VERSION ""

NS_ :

BS_:

BU_: GearboxECU EngineECU

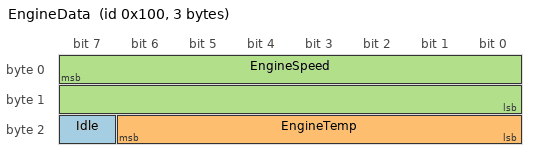
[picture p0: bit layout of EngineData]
BO_ 256 EngineData: 3 EngineECU
 SG_ Idle : 23|1@0+ (1,0) [0|1] "" Vector__XXX
 SG_ EngineTemp : 22|7@0+ (2,-50) [-50|204] "¡ÆC" Vector__XXX
 SG_ EngineSpeed : 7|16@0+ (1,0) [0|65535] "rpm"  GearboxECU

EV_ EnvKlemme30: 0 [0|1] "" 1 1 DUMMY_NODE_VECTOR0 Vector__XXX;

EV_ EnvKlemme15: 0 [0|1] "" 0 2 DUMMY_NODE_VECTOR0 Vector__XXX;

BA_DEF_ BU_  "NodeLayerModules" STRING ;
BA_DEF_ BO_  "GenMsgILSupport" ENUM  "No","Yes";
BA_DEF_  "NmBaseAddress" HEX 1024 1087;
BA_DEF_ BO_  "GenMsgCycleTime" INT 0 50000;
BA_DEF_ BO_  "GenMsgSendType" ENUM  "Cyclic","NotUsed","NotUsed","NotUsed","NotUsed","NotUsed","NotUsed","IfActive","NoMsgSendType","NotUsed","vector_leerstring";
BA_DEF_ SG_  "GenSigSendType" ENUM  "Cyclic","OnWrite","OnWriteWithRepetition","OnChange","OnChangeWithRepetition","IfActive","IfActiveWithRepetition","NoSigSendType","NotUsed","NotUsed","NotUsed","NotUsed","NotUsed";
BA_DEF_ SG_  "GenSigStartValue" FLOAT 0 100000000000;
BA_DEF_DEF_  "NodeLayerModules" "CANoeILNLVector.dll";
BA_DEF_DEF_  "GenMsgILSupport" "Yes";
BA_DEF_DEF_  "NmBaseAddress" 1024;
BA_DEF_DEF_  "GenMsgCycleTime" 0;
BA_DEF_DEF_  "GenMsgSendType" "NoMsgSendType";
BA_DEF_DEF_  "GenSigSendType" "Cyclic";
BA_DEF_DEF_  "GenSigStartValue" 0;
BA_ "GenMsgSendType" BO_ 256 0;
BA_ "GenMsgCycleTime" BO_ 256 300;
BA_ "GenSigStartValue" SG_ 256 EngineTemp 25;
